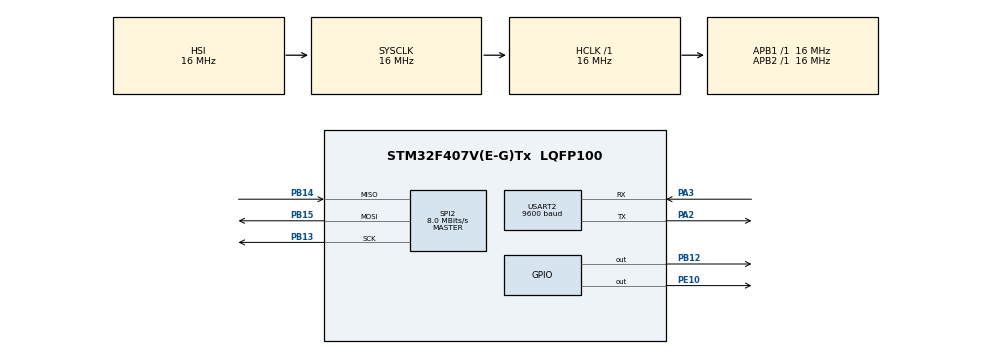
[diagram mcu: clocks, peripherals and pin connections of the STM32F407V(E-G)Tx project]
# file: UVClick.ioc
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Mcu.Family=STM32F4
RCC.CortexFreq_Value=16000000
SPI2.VirtualType=VM_MASTER
PB15.Signal=SPI2_MOSI
PB13.Signal=SPI2_SCK
USART2.BaudRate=9600
ProjectManager.StackSize=0x400
PA3.Mode=Asynchronous
ProjectManager.TargetToolchain=STM32CubeIDE
RCC.LSE_VALUE=32768
RCC.AHBFreq_Value=16000000
PB14.Signal=SPI2_MISO
RCC.HSE_VALUE=25000000
board=custom
RCC.VCOOutputFreq_Value=192000000
PB15.Mode=Full_Duplex_Master
RCC.APB2Freq_Value=16000000
PB14.Mode=Full_Duplex_Master
SPI2.CalculateBaudRate=8.0 MBits/s
PE10.Signal=GPIO_Output
Mcu.Name=STM32F407V(E-G)Tx
PA2.Signal=USART2_TX
RCC.SYSCLKFreq_VALUE=16000000
Mcu.Package=LQFP100
SPI2.Mode=SPI_MODE_MASTER
USART2.VirtualMode=VM_ASYNC
ProjectManager.HeapSize=0x200
RCC.HSI_VALUE=16000000
NVIC.PriorityGroup=NVIC_PRIORITYGROUP_4
PA2.Mode=Asynchronous
SPI2.Direction=SPI_DIRECTION_2LINES
PB13.Mode=Full_Duplex_Master
RCC.APB1Freq_Value=16000000
PB12.Signal=GPIO_Output
PA3.Signal=USART2_RX

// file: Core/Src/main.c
/* USER CODE BEGIN Header */
/**
  ******************************************************************************
  * @file           : main.c
  * @brief          : Main program body
  ******************************************************************************
  * @attention
  *
  * <h2><center>&copy; Copyright (c) 2021 STMicroelectronics.
  * All rights reserved.</center></h2>
  *
  * This software component is licensed by ST under BSD 3-Clause license,
  * the "License"; You may not use this file except in compliance with the
  * License. You may obtain a copy of the License at:
  *                        opensource.org/licenses/BSD-3-Clause
  *
  ******************************************************************************
  */
/* USER CODE END Header */
#include "main.h"
#include "spi.h"
#include "usart.h"
#include "gpio.h"

/* USER CODE BEGIN Includes */
#include "bsp/uv_click.h"
/* USER CODE END Includes */

void SystemClock_Config(void);

int main(void)
{

  /* MCU Configuration--------------------------------------------------------*/

  /* Reset of all peripherals, Initializes the Flash interface and the Systick. */
  HAL_Init();

  /* Configure the system clock */
  SystemClock_Config();

  /* Initialize all configured peripherals */
  MX_GPIO_Init();
  MX_SPI2_Init();
  MX_USART2_UART_Init();

  /* USER CODE BEGIN 2 */

  float uv_data = 0.0f;

  UV_Click_Init();

  /* USER CODE END 2 */

  /* Infinite loop */
  /* USER CODE BEGIN WHILE */
  while (1)
  {
	uv_data = Get_UV_Value(&hspi2);
	UART_Send_Data(uv_data, &huart2);

	HAL_Delay(200);

    /* USER CODE END WHILE */

  }
}

void SystemClock_Config(void)
{
  RCC_OscInitTypeDef RCC_OscInitStruct = {0};
  RCC_ClkInitTypeDef RCC_ClkInitStruct = {0};

  /** Configure the main internal regulator output voltage
  */
  __HAL_RCC_PWR_CLK_ENABLE();
  __HAL_PWR_VOLTAGESCALING_CONFIG(PWR_REGULATOR_VOLTAGE_SCALE1);
  /** Initializes the RCC Oscillators according to the specified parameters
  * in the RCC_OscInitTypeDef structure.
  */
  RCC_OscInitStruct.OscillatorType = RCC_OSCILLATORTYPE_HSI;
  RCC_OscInitStruct.HSIState = RCC_HSI_ON;
  RCC_OscInitStruct.HSICalibrationValue = RCC_HSICALIBRATION_DEFAULT;
  RCC_OscInitStruct.PLL.PLLState = RCC_PLL_NONE;
  if (HAL_RCC_OscConfig(&RCC_OscInitStruct) != HAL_OK)
  {
    Error_Handler();
  }
  /** Initializes the CPU, AHB and APB buses clocks
  */
  RCC_ClkInitStruct.ClockType = RCC_CLOCKTYPE_HCLK|RCC_CLOCKTYPE_SYSCLK
                              |RCC_CLOCKTYPE_PCLK1|RCC_CLOCKTYPE_PCLK2;
  RCC_ClkInitStruct.SYSCLKSource = RCC_SYSCLKSOURCE_HSI;
  RCC_ClkInitStruct.AHBCLKDivider = RCC_SYSCLK_DIV1;
  RCC_ClkInitStruct.APB1CLKDivider = RCC_HCLK_DIV1;
  RCC_ClkInitStruct.APB2CLKDivider = RCC_HCLK_DIV1;

  if (HAL_RCC_ClockConfig(&RCC_ClkInitStruct, FLASH_LATENCY_0) != HAL_OK)
  {
    Error_Handler();
  }
}

void Error_Handler(void)
{
  __disable_irq();
  while (1)
  {
  }
}

/************************ (C) COPYRIGHT STMicroelectronics *****END OF FILE****/
